# A33G52x register map
Vendor: ABOV Semiconductor Co., Ltd.; File version: 0.1
CPU: CM3 r1p0, little endian, no MPU, no FPU, 3 interrupt priority bits
Registers are 32-bit, read-write, reset 0x0 unless marked. A register's access mark holds for its fields unless they carry their own. Offsets are from the block's base; [hi:lo] are bit positions; {n}, {i} and the like mark numbered series.

## PA — GENERAL PURPOSE I/O
Base 0x40000300
Same registers: PB 0x40000310, PC 0x40000320, PD 0x40000330, PE 0x40000340, PF 0x40000350
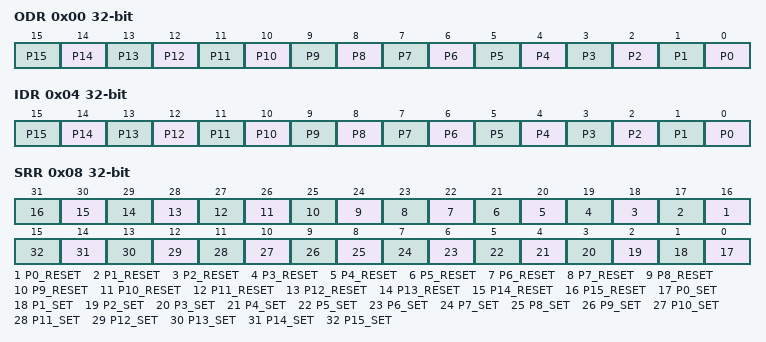
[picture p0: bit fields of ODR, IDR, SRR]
0x00 ODR — PORT n Output Data Register
  [n] P{n} (n=0..15) — P{n} Output level
0x04 IDR ro — PORT n Input Data Register
  [n] P{n} (n=0..15) — P{n} Input level
0x08 SRR — Port n Set/Reset Register
  [n+16] P{n}_RESET wo (n=0..15) — P{n} bit reset
  [n] P{n}_SET wo (n=0..15) — P{n} bit set

## WDT — WATCH-DOG TIMER
Base 0x40000400
0x00 LR — Watchdog Timer Load Register
0x04 CVR ro reset 0xFFFF — WDT Counter Value Register
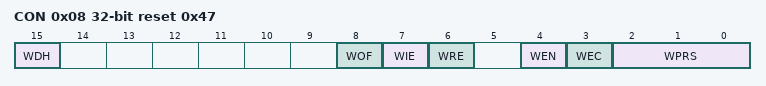
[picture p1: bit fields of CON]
0x08 CON reset 0x47 (reset mask 0x81EF) — WDT Control Register
  [15] WDH — WDT operation in debug mode
  [8] WOF — WDT underflow falg
  [7] WIE — WDT interrupt enable
  [6] WRE — WDT interrupt reset
  [4] WEN — WDT counter enable
  [3] WEC — WDTCLKIN clock source select
  [2:0] WPRS — counter prescaler

## FRT — Free-Run Timer
Base 0x40000500
0x00 PRD — FRT Period Register
0x04 CNT — FRT Count Register
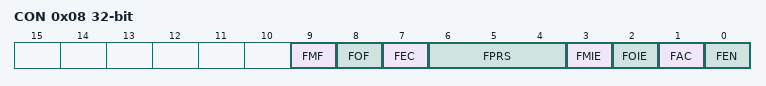
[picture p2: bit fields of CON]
0x08 CON — FRT Control Register
  [9] FMF — FRT Match event has occurred
  [8] FOF — FRT Overflow event has occurred
  [7] FEC — FRT Select a clock source
  [6:4] FPRS — FRT clock div
  [3] FMIE — FRT match interrupt enable
  [2] FOIE — FRT Overflow interrupt
  [1] FAC — FRT free-run mode/periodic mode
  [0] FEN — FRT counter enable

## T0 — 16-BIT TIMER
Base 0x40000C00
Same registers: T{n} {0x40000C00+0x20*n} (n=1..9)
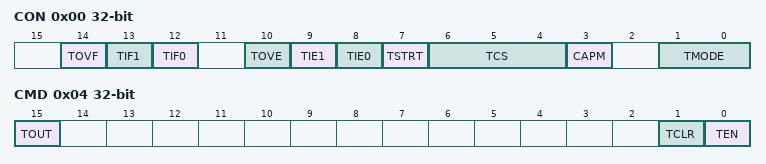
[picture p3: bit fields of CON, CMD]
0x00 CON — Timer n Control Register
  [14] TOVF — Overflow Occurred (write 1 to clar the flag)
  [13] TIF1 — Match1 interrupt occurred(write 1 to clear the flag)
  [12] TIF0 — Match0 interrupt occurred(write 1 to clear the flag)
  [10] TOVE — Enable overflow interrupt
  [9] TIE1 — Enable match1 interrupt
  [8] TIE0 — Enable match0 interrupt
  [7] TSTRT — Initial output of each mode
  [6:4] TCS — Select the clock source
  [3] CAPM — Rising-edge clear mode/Falling-edge clear mode
  [1:0] TMODE — Timer operation mode
0x04 CMD — Timer n Command Register
  [15] TOUT ro — Timer Output state
  [1] TCLR wo — No effect/Initialize Timer.
  [0] TEN — Timer enable bit
0x08 GRA — Timer n General Purpose Register A
  [15:0] GRA — General Purpose Register A
0x0C TnGRB — Timer n General Register B
  [15:0] GRB
0x10 PRS — Timer n Prescaler Register
  [9:0] PRS — Input clock prescaler value
0x14 CNT — Timer n Count Register
  [15:0] CNT

## PWM0 — PWM Generator
Base 0x40000700
Same registers: PWM1 0x40000720, PWM2 0x40000740, PWM3 0x40000760, PWM4 0x40000780, PWM5 0x400007A0, PWM6 0x400007C0, PWM7 0x400007E0
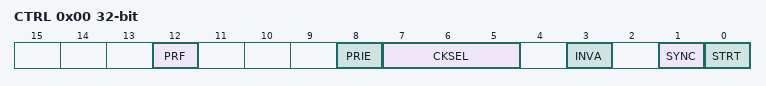
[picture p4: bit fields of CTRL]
0x00 CTRL — PWM n Control Register
  [12] PRF — Periodic interrupt occurs (write 1 to clear)
  [8] PRIE — Enable periodic interrupt
  [7:5] CKSEL — input clock divided
  [3] INVA — Inverted output
  [1] SYNC — Synchronize this channel to the other channels
  [0] STRT — startPWM counter
0x04 CNT — PWM n Counter Register
  [15:0] CNT — Current counter value
0x08 PER — PWM n Counter Period Register
  [15:0] PERIOD — PWM period value
0x0C CMP — PWM n Compare Register
  [15:0] CMP — Comparator value

## PWMPRS0
Base 0x4000077C
Same registers: PWMPRS1 0x400007FC
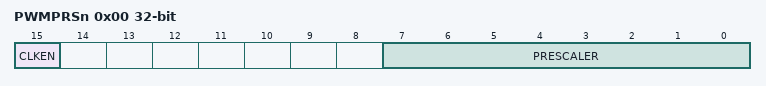
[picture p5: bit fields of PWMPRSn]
0x00 PWMPRSn — PWM Prescaler Register n
  [15] CLKEN — Stop/Run prescaler n clock
  [7:0] PRESCALER — Prescaler value of unit n

## I2C0 — I2C Interface
Base 0x40000A00
Same registers: I2C1 0x40000A80
0x00 DR — I2C Data Register
  [7:0] ICDR — In transmit mode, stored data is sent to data line (SDA)
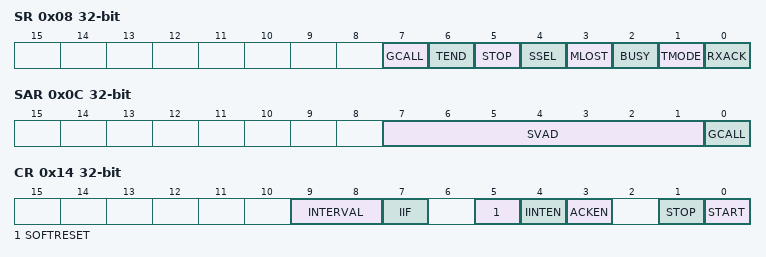
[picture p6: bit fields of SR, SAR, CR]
0x08 SR — Status register
  [7] GCALL — General call flag
  [6] TEND — 1-byte transmission complete flag
  [5] STOP — Stop Flag
  [4] SSEL — slave flag
  [3] MLOST — Mastership lost flag
  [2] BUSY — busy flag
  [1] TMODE — Transmit/reciever mode flag
  [0] RXACK — RX ack flag
0x0C SAR — I2C Slave Address Register
  [7:1] SVAD — 7 bits slave address
  [0] GCALL — General call control
0x14 CR — I2C Control Register
  [9:8] INTERVAL — Internal Delay add options
  [7] IIF ro — IIF represent interrupt generation
  [5] SOFTRESET — Reset registers in serial devices
  [4] IINTEN — Enable interrupt request
  [3] ACKEN — ACK enabit bit in receiver mode
  [1] STOP — Stop enable bit
  [0] START — This field is used to start in mater mode.
0x18 SCLL reset 0xFF — I2C SCL LOW duration Register
  [15:0] SCLL — SCL Low duration value
0x1C SCLH reset 0xFFFF — I2C SCL HIGH duration Register
  [15:0] SCLH — SCL High duration value
0x20 SDH reset 0xFFFF — I2C SDA Hold Register
  [1:0] SDH — Set SDA Hold time
